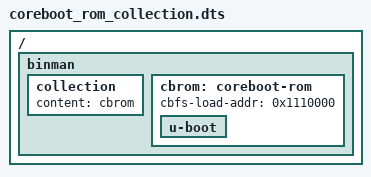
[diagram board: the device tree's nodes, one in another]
// SPDX-License-Identifier: GPL-2.0+

/dts-v1/;

/ {
	#address-cells = <1>;
	#size-cells = <1>;

	binman {
		collection {
			content = <&cbrom>;
		};
		cbrom: coreboot-rom {
			cbfs-load-addr = <0x1110000>;
			u-boot {
			};
		};
	};
};
